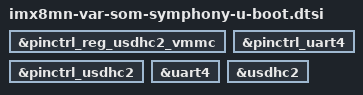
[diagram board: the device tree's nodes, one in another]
// SPDX-License-Identifier: GPL-2.0+
/*
 * Copyright 2021 Collabora Ltd.
 */

#include "imx8mn-var-som-u-boot.dtsi"

&pinctrl_reg_usdhc2_vmmc {
	bootph-pre-ram;
};

&pinctrl_uart4 {
	bootph-pre-ram;
};

&pinctrl_usdhc2 {
	bootph-pre-ram;
};

&uart4 {
	bootph-pre-ram;
};

&usdhc2 {
	bootph-pre-ram;
};
